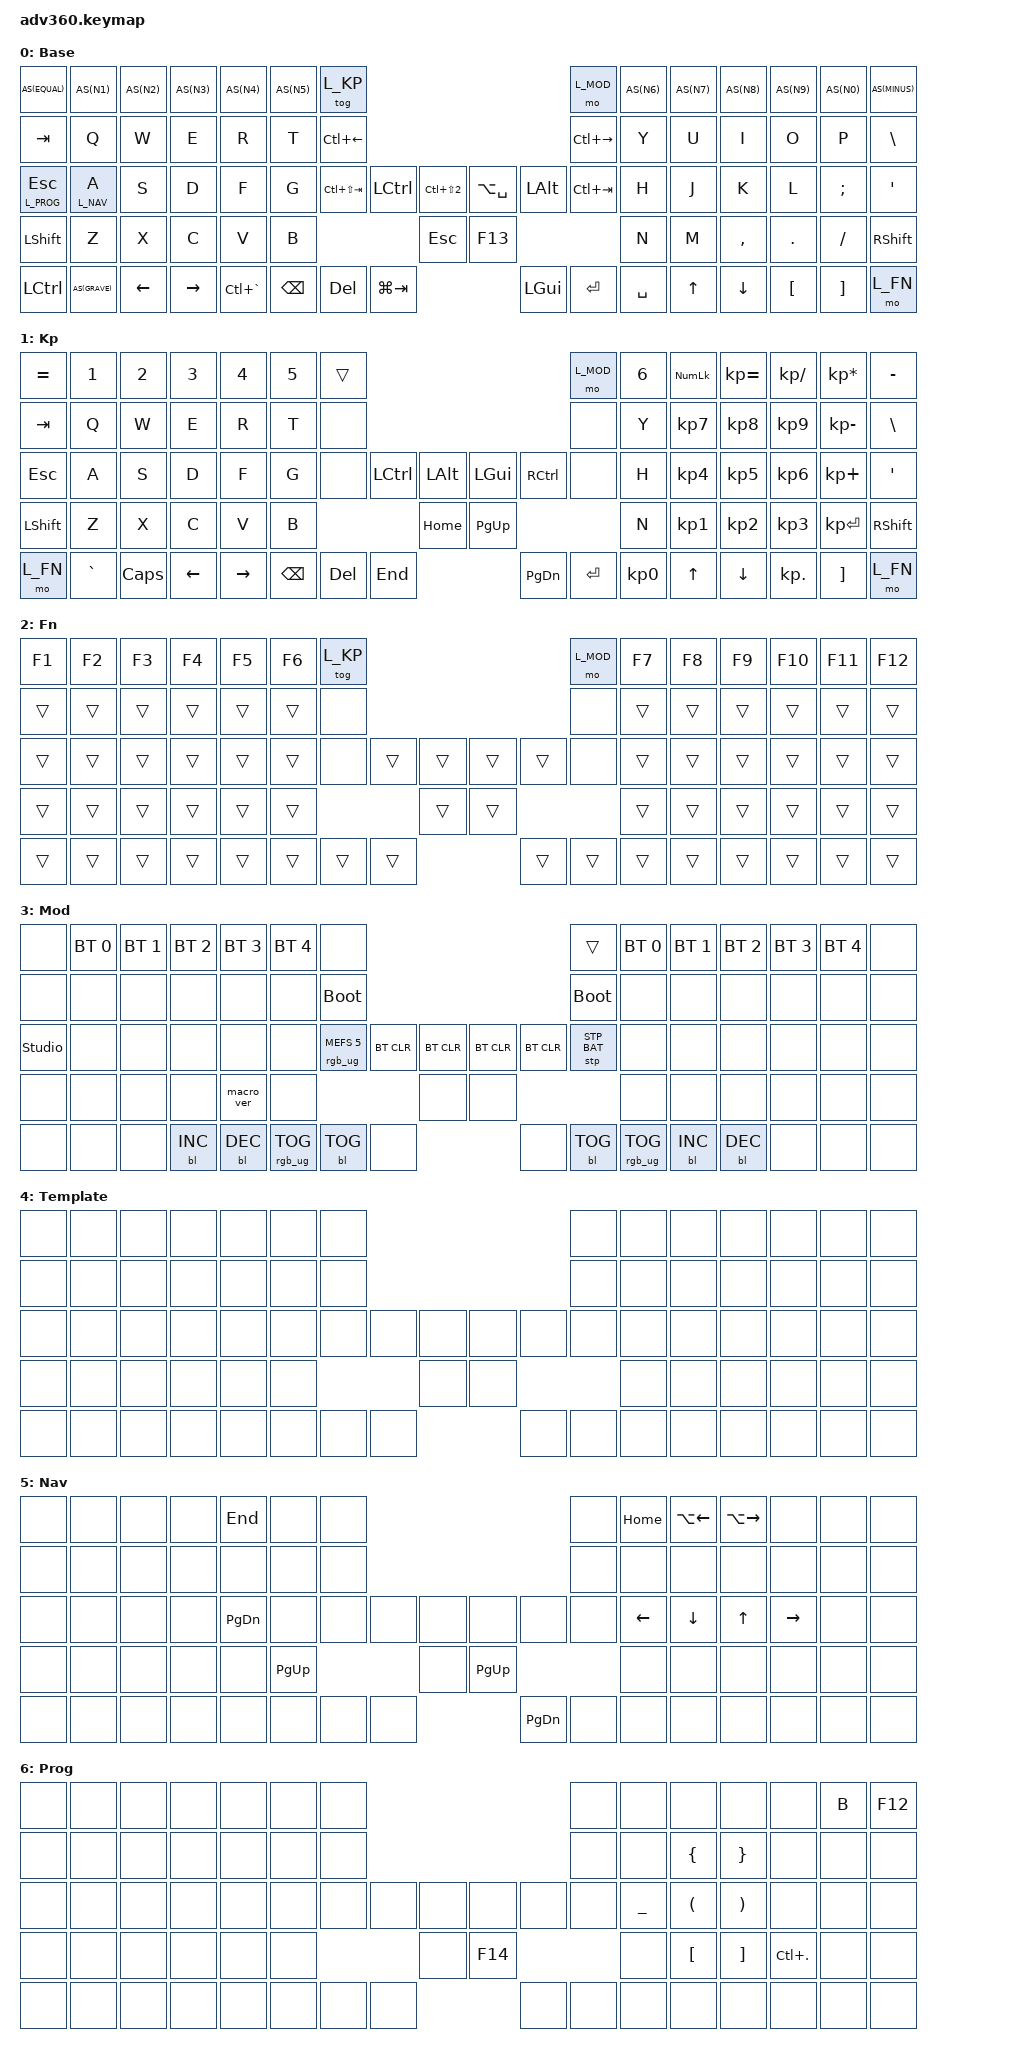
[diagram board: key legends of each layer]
#include <behaviors.dtsi>
#include <dt-bindings/zmk/keys.h>
#include <dt-bindings/zmk/bt.h>
#include <dt-bindings/zmk/rgb.h>
#include <dt-bindings/zmk/stp.h>
#include <dt-bindings/zmk/backlight.h>
#include <dt-bindings/zmk/pointing.h>

// remember: on macOS, LG is cmd key
#define HYP(key)  LS(LC(LA(LG(key))))
#define HYPER     LS(LC(LA(LGUI)))

#define L_BASE 0
#define L_KP   1
#define L_FN   2
#define L_MOD  3
#define L_NONE 4
#define L_NAV  5
#define L_PROG 6

#define AS(keycode) &as LS(keycode) keycode     // autoshift, references behavior `as`

/ {
  behaviors {
    #include "macros.dtsi"
    #include "version.dtsi"
    #ifndef VERSION_MACRO
    macro_ver: macro_ver {
      compatible = "zmk,behavior-macro";
      label = "macro_version";
      #binding-cells = <0>;
      bindings = <&kp RET>;
    };
    #endif

    as: auto_shift {
      compatible = "zmk,behavior-hold-tap";
      label = "AUTO_SHIFT";
      #binding-cells = <2>;
      tapping_term_ms = <270>;
      quick_tap_ms = <0>;
      flavor = "tap-preferred";
      bindings = <&kp>, <&kp>;
    };
  };

  keymap {
    compatible = "zmk,keymap";

    // index: 0 L_BASE
    default_layer {
      display-name = "Base";
      bindings = <
        AS(EQUAL)      AS(N1)      AS(N2)   AS(N3)    AS(N4)        AS(N5) &tog L_KP                                                                           &mo L_MOD     AS(N6) AS(N7) AS(N8)    AS(N9)   AS(N0)   AS(MINUS)
        &kp TAB        &kp Q       &kp W    &kp E     &kp R         &kp T  &kp LC(LEFT)                                                                        &kp LC(RIGHT) &kp Y  &kp U  &kp I     &kp O    &kp P    &kp BSLH
        &lt L_PROG ESC &lt L_NAV A &kp S    &kp D     &kp F         &kp G  &kp LC(LS(TAB))          &kp LCTRL &kp LC(LS(N2)) &kp LA(SPACE) &kp LALT            &kp LC(TAB)   &kp H  &kp J  &kp K     &kp L    &kp SEMI &kp SQT
        &kp LSHFT      &kp Z       &kp X    &kp C     &kp V         &kp B                                     &kp ESC        &kp F13                                         &kp N  &kp M  &kp COMMA &kp DOT  &kp FSLH &kp RSHFT
        &kp LCTRL      AS(GRAVE)   &kp LEFT &kp RIGHT &kp LC(GRAVE)                        &kp BSPC &kp DEL   &kp LG(TAB)    &kp LGUI      &kp ENTER &kp SPACE                      &kp UP &kp DOWN  &kp LBKT &kp RBKT &mo L_FN
      >;
    };

    // keypad layer from Kinesis
    // index: 1 L_KP
    keypad {
      display-name = "Kp";
      bindings = <
        &kp EQUAL &kp N1    &kp N2   &kp N3   &kp N4     &kp N5 &trans                                                           &mo L_MOD &kp N6 &kp KP_NUM &kp KP_EQUAL &kp KP_DIVIDE &kp KP_MULTIPLY &kp MINUS
        &kp TAB   &kp Q     &kp W    &kp E    &kp R      &kp T  &none                                                            &none     &kp Y  &kp KP_N7  &kp KP_N8    &kp KP_N9     &kp KP_MINUS    &kp BSLH
        &kp ESC   &kp A     &kp S    &kp D    &kp F      &kp G  &none              &kp LCTRL &kp LALT &kp LGUI  &kp RCTRL        &none     &kp H  &kp KP_N4  &kp KP_N5    &kp KP_N6     &kp KP_PLUS     &kp SQT
        &kp LSHFT &kp Z     &kp X    &kp C    &kp V      &kp B                               &kp HOME &kp PG_UP                            &kp N  &kp KP_N1  &kp KP_N2    &kp KP_N3     &kp KP_ENTER    &kp RSHFT
        &mo L_FN  &kp GRAVE &kp CAPS &kp LEFT &kp RIGHT                   &kp BSPC &kp DEL   &kp END  &kp PG_DN &kp ENTER &kp KP_N0               &kp UP     &kp DOWN     &kp KP_DOT    &kp RBKT        &mo L_FN
      >;
    };

    // fn layer from Kinesis
    // index: 2 L_FN
    fn {
      display-name = "Fn";
      bindings = <
        &kp F1 &kp F2 &kp F3 &kp F4 &kp F5 &kp F6 &tog L_KP                                        &mo L_MOD &kp F7 &kp F8 &kp F9 &kp F10 &kp F11 &kp F12
        &trans &trans &trans &trans &trans &trans &none                                            &none     &trans &trans &trans &trans  &trans  &trans
        &trans &trans &trans &trans &trans &trans &none         &trans &trans &trans &trans        &none     &trans &trans &trans &trans  &trans  &trans
        &trans &trans &trans &trans &trans &trans                      &trans &trans                         &trans &trans &trans &trans  &trans  &trans
        &trans &trans &trans &trans &trans               &trans &trans &trans &trans &trans &trans                  &trans &trans &trans  &trans  &trans
      >;
    };

    // mod layer from Kinesis
    // index: 3 L_MOD
    mod {
      display-name = "Mod";
      bindings = <
        &none &bt BT_SEL 0 &bt BT_SEL 1 &bt BT_SEL 2 &bt BT_SEL 3 &bt BT_SEL 4 &none                                                                                              &trans                 &bt BT_SEL 0 &bt BT_SEL 1 &bt BT_SEL 2 &bt BT_SEL 3 &bt BT_SEL 4 &none
        &none &none        &none        &none        &none        &none        &bootloader                                                                                        &bootloader            &none        &none        &none        &none        &none        &none
        &studio_unlock &none        &none        &none        &none        &none        &rgb_ug RGB_MEFS_CMD 5                 &bt BT_CLR &bt BT_CLR &bt BT_CLR &bt BT_CLR                 &stp STP_BAT &none        &none        &none        &none        &none        &none
        &none &none        &none        &none        &macro_ver   &none                                                          &none      &none                                                        &none        &none        &none        &none        &none        &none
        &none &none        &none        &bl BL_INC   &bl BL_DEC                                       &rgb_ug RGB_TOG &bl BL_TOG &none      &none      &bl BL_TOG &rgb_ug RGB_TOG                                     &bl BL_INC   &bl BL_DEC   &none        &none        &none
      >;
    };

    // template layer by willi
    // index: 4 L_NONE
    none {
      display-name = "Template";
      bindings = <
        &none &none &none &none &none &none &none                                           &none &none &none &none &none &none &none
        &none &none &none &none &none &none &none                                           &none &none &none &none &none &none &none
        &none &none &none &none &none &none &none          &none &none &none &none          &none &none &none &none &none &none &none
        &none &none &none &none &none &none                      &none &none                      &none &none &none &none &none &none
        &none &none &none &none &none                &none &none &none &none &none &none                &none &none &none &none &none
      >;
    };
 
    // vim-like nav layer by willi
    // invoked via &lt from default
    // index: 5 L_NAV
    nav {
      display-name = "Nav";
      bindings = <
        &none &none &none &none &kp END   &none     &none                                         &none &kp HOME &kp LA(LEFT) &kp LA(RIGHT) &none     &none &none
        &none &none &none &none &none     &none     &none                                         &none &none    &none        &none         &none     &none &none
        &none &none &none &none &kp PG_DN &none     &none       &none &none &none     &none       &none &kp LEFT &kp DOWN     &kp UP        &kp RIGHT &none &none
        &none &none &none &none &none     &kp PG_UP                   &none &kp PG_UP                   &none    &none        &none         &none     &none &none
        &none &none &none &none &none                     &none &none &none &kp PG_DN &none &none                &none        &none         &none     &none &none 
      >;
    };         

    // programming helper layer by willi
    // invoked via &lt from default
    // index: 6 L_PROG
    prog {
      display-name = "Prog";
      bindings = <                                                                                                                               
        &none &none &none &none &none &none &none                                           &none &none     &none    &none    &none &kp B &kp F12
        &none &none &none &none &none &none &none                                           &none &none     &kp LBRC &kp RBRC &none &none &none
        &none &none &none &none &none &none &none          &none &none &none &none          &none &kp UNDER &kp LPAR &kp RPAR &none &none &none
        &none &none &none &none &none &none                      &none &kp F14                    &none     &kp LBKT &kp RBKT &kp LC(DOT) &none &none
        &none &none &none &none &none                &none &none &none &none &none &none                    &none    &none    &none &none &none
      >;
    };

    extra1 { 
      display-name = "Red";    
      status = "reserved";
    };

    extra2 { 
      display-name = "Purple";    
      status = "reserved";
    };

    extra3 { 
      display-name = "Cyan";    
      status = "reserved";
    };

    extra4 { 
      display-name = "Yellow";    
      status = "reserved";
    };
  };
};
